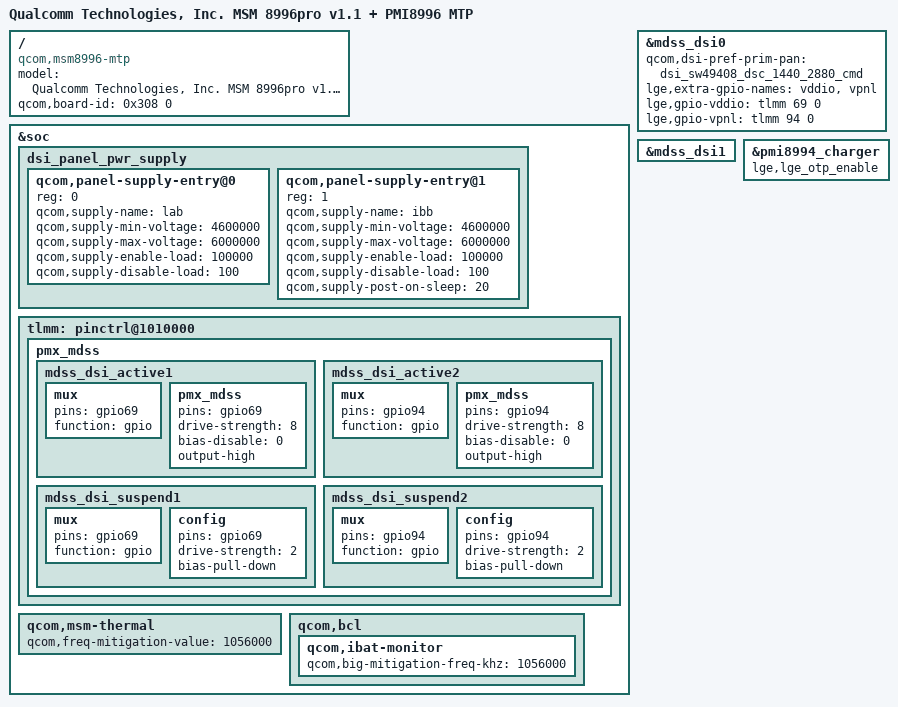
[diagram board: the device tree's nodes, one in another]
/* Copyright (c) 2015, The Linux Foundation. All rights reserved.
 *
 * This program is free software; you can redistribute it and/or modify
 * it under the terms of the GNU General Public License version 2 and
 * only version 2 as published by the Free Software Foundation.
 *
 * This program is distributed in the hope that it will be useful,
 * but WITHOUT ANY WARRANTY; without even the implied warranty of
 * MERCHANTABILITY or FITNESS FOR A PARTICULAR PURPOSE.  See the
 * GNU General Public License for more details.
 */


/dts-v1/;

#include "../../../qcom/msm8996pro-v1.1.dtsi"
#include "../../../qcom/msm-pmi8996.dtsi"
#include "../../../qcom/msm8996-mtp.dtsi"
#include "msm8996-lucye_tmo_us.dtsi"
#include "msm8996-lucye_tmo_us-sound.dtsi"

/ {
	model = "Qualcomm Technologies, Inc. MSM 8996pro v1.1 + PMI8996 MTP";
	compatible = "qcom,msm8996-mtp", "qcom,msm8996", "qcom,mtp";
	qcom,board-id = <0x308 0>;
};

/* Display Function */
&soc {
	dsi_panel_pwr_supply: dsi_panel_pwr_supply {
		#address-cells = <1>;
		#size-cells = <0>;

		qcom,panel-supply-entry@0 {
			reg = <0>;
			qcom,supply-name = "lab";
			qcom,supply-min-voltage = <4600000>;
			qcom,supply-max-voltage = <6000000>;
			qcom,supply-enable-load = <100000>;
			qcom,supply-disable-load = <100>;
		};

		qcom,panel-supply-entry@1 {
			reg = <1>;
			qcom,supply-name = "ibb";
			qcom,supply-min-voltage = <4600000>;
			qcom,supply-max-voltage = <6000000>;
			qcom,supply-enable-load = <100000>;
			qcom,supply-disable-load = <100>;
			qcom,supply-post-on-sleep = <20>;
		};
	};
};

&mdss_dsi0 {
	qcom,dsi-pref-prim-pan = <&dsi_sw49408_dsc_1440_2880_cmd>;
	lge,extra-gpio-names = "vddio", "vpnl";

	lge,gpio-vddio = <&tlmm 69 0>;
	lge,gpio-vpnl = <&tlmm 94 0>;
};

&mdss_dsi1 {
	/delete-property/cell-index;
};

/* pinctrl for Display function
 * GPIO69 : LCD_VDD_IO_EN
 * GPIO94 : LCD_VCL_EN
 */
&soc {
	tlmm: pinctrl@1010000 {
		pmx_mdss: pmx_mdss {
			mdss_dsi_active1: mdss_dsi_active1 {
				mux {
					pins = "gpio69";
					function = "gpio";
				};

				pmx_mdss {
					pins = "gpio69";
					drive-strength = <8>; /* 8 mA */
					bias-disable = <0>; /* no pull */
					output-high;
				};
			};
			mdss_dsi_active2: mdss_dsi_active2 {
				mux {
					pins = "gpio94";
					function = "gpio";
				};

				pmx_mdss {
					pins = "gpio94";
					drive-strength = <8>; /* 8 mA */
					bias-disable = <0>; /* no pull */
					output-high;
				};
			};
			mdss_dsi_suspend1: mdss_dsi_suspend1 {
				mux {
					pins = "gpio69";
					function = "gpio";
				};

				config {
					pins = "gpio69";
					drive-strength = <2>; /* 2 mA */
					bias-pull-down; /* pull down */
				};
			};
			mdss_dsi_suspend2: mdss_dsi_suspend2 {
				mux {
					pins = "gpio94";
					function = "gpio";
				};

				config {
					pins = "gpio94";
					drive-strength = <2>; /* 2 mA */
					bias-pull-down; /* pull down */
				};
			};
		};
	};
};

&pmi8994_charger {
    lge,lge_otp_enable;
};

&soc {
	qcom,msm-thermal {
		qcom,freq-mitigation-value = <1056000>;
	};
	qcom,bcl {
		qcom,ibat-monitor {
			qcom,big-mitigation-freq-khz = <1056000>;
		};
	};
};
